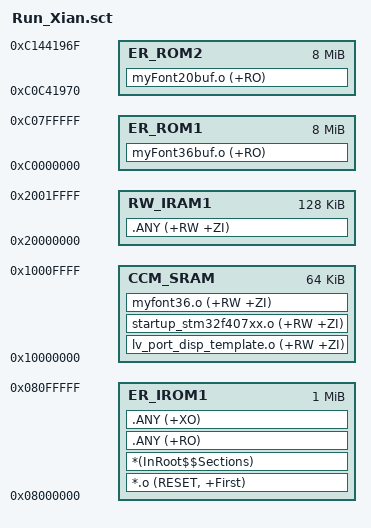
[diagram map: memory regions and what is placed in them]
; *************************************************************
; *** Scatter-Loading Description File generated by uVision ***
; *************************************************************

LR_IROM1 0x08000000 0x00100000  {    ; load region size_region
  ER_IROM1 0x08000000 0x00100000  {  ; load address = execution address
   *.o (RESET, +First)
   *(InRoot$$Sections)
   .ANY (+RO)
   .ANY (+XO)
  }
  RW_IRAM1 0x20000000 0x00020000  {  ; RW data
   .ANY (+RW +ZI)
  }
  CCM_SRAM 0x10000000 0x00010000 {
  lv_port_disp_template.o (+RW +ZI)
  startup_stm32f407xx.o (+RW +ZI)
  myfont36.o (+RW +ZI)
  }
}

LR_ROM1 0xC0000000 0x00800000  {
  ER_ROM1 0xC0000000 0x00800000  {  ; load address = execution address
    myFont36buf.o (+RO)
  }
}
LR_ROM2 0xC0C41970 0x00800000  {
  ER_ROM2 0xC0C41970 0x00800000  {  ; load address = execution address
    myFont20buf.o (+RO)
  }
}
